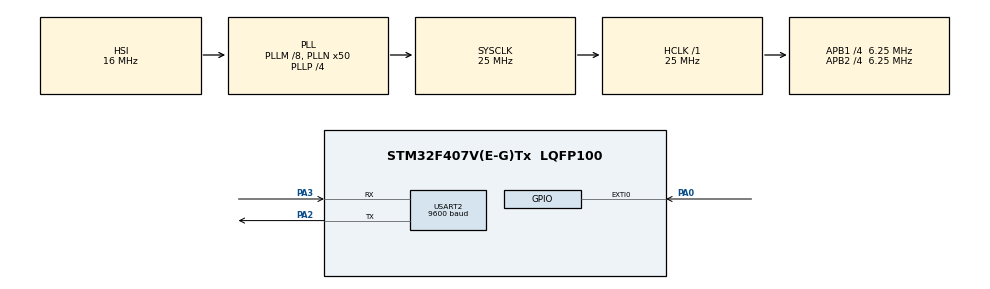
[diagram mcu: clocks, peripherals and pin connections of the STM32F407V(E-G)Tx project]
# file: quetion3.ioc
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Mcu.Family=STM32F4
RCC.CortexFreq_Value=25000000
RCC.APB1CLKDivider=RCC_HCLK_DIV4
NVIC.USART2_IRQn=true\:0\:0\:false\:false\:true\:true\:true
USART2.BaudRate=9600
RCC.SYSCLKSource=RCC_SYSCLKSOURCE_PLLCLK
ProjectManager.StackSize=0x400
PA0-WKUP.Signal=GPXTI0
PA3.Mode=Asynchronous
ProjectManager.TargetToolchain=STM32CubeIDE
RCC.HCLKFreq_Value=25000000
RCC.APB2TimFreq_Value=12500000
RCC.AHBFreq_Value=25000000
RCC.HSE_VALUE=8000000
board=STM32F407G-DISC1
RCC.VCOOutputFreq_Value=100000000
RCC.APB2Freq_Value=6250000
Mcu.Name=STM32F407V(E-G)Tx
PA2.Signal=USART2_TX
RCC.48MHZClocksFreq_Value=14285714.285714285
NVIC.EXTI0_IRQn=true\:0\:0\:false\:false\:true\:true\:true
RCC.SYSCLKFreq_VALUE=25000000
Mcu.Package=LQFP100
USART2.VirtualMode=VM_ASYNC
ProjectManager.HeapSize=0x200
RCC.HSI_VALUE=16000000
RCC.PLLP=RCC_PLLP_DIV4
RCC.PLLQ=7
NVIC.PriorityGroup=NVIC_PRIORITYGROUP_0
RCC.APB2CLKDivider=RCC_HCLK_DIV4
RCC.PLLM=8
RCC.PLLN=50
RCC.APB1TimFreq_Value=12500000
PA2.Mode=Asynchronous
RCC.APB1Freq_Value=6250000
PA3.Signal=USART2_RX

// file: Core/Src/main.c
/* USER CODE BEGIN Header */
/**
  ******************************************************************************
  * @file           : main.c
  * @brief          : Main program body
  ******************************************************************************
  * @attention
  *
  * <h2><center>&copy; Copyright (c) 2022 STMicroelectronics.
  * All rights reserved.</center></h2>
  *
  * This software component is licensed by ST under Ultimate Liberty license
  * SLA0044, the "License"; You may not use this file except in compliance with
  * the License. You may obtain a copy of the License at:
  *                             www.st.com/SLA0044
  *
  ******************************************************************************
  */
/* USER CODE END Header */
#include "main.h"

/* USER CODE BEGIN Includes */
#include<stdio.h>
#include<string.h>

/* USER CODE END Includes */

UART_HandleTypeDef huart2;

/* USER CODE BEGIN PV */
volatile int switch_flag = 0;

/* USER CODE END PV */

void SystemClock_Config(void);
static void MX_GPIO_Init(void);
static void MX_USART2_UART_Init(void);

int main(void)
{
  /* USER CODE BEGIN 1 */
	char str[64];
	int count = 0;

  /* USER CODE END 1 */

  /* MCU Configuration--------------------------------------------------------*/

  /* Reset of all peripherals, Initializes the Flash interface and the Systick. */
  HAL_Init();

  /* Configure the system clock */
  SystemClock_Config();

  /* Initialize all configured peripherals */
  MX_GPIO_Init();
  MX_USART2_UART_Init();

  /* Infinite loop */
  while (1)
  {
	  if(switch_flag == 1)
	  {
		  count++;

		  sprintf(str,"Count = %d\r\n",count);
		  HAL_UART_Transmit_IT(&huart2, (uint8_t*)str, strlen(str));
		  HAL_Delay(1000);
		  switch_flag =0;
	  }

  }
}

void SystemClock_Config(void)
{
  RCC_OscInitTypeDef RCC_OscInitStruct = {0};
  RCC_ClkInitTypeDef RCC_ClkInitStruct = {0};

  /** Configure the main internal regulator output voltage
  */
  __HAL_RCC_PWR_CLK_ENABLE();
  __HAL_PWR_VOLTAGESCALING_CONFIG(PWR_REGULATOR_VOLTAGE_SCALE1);
  /** Initializes the RCC Oscillators according to the specified parameters
  * in the RCC_OscInitTypeDef structure.
  */
  RCC_OscInitStruct.OscillatorType = RCC_OSCILLATORTYPE_HSI;
  RCC_OscInitStruct.HSIState = RCC_HSI_ON;
  RCC_OscInitStruct.HSICalibrationValue = RCC_HSICALIBRATION_DEFAULT;
  RCC_OscInitStruct.PLL.PLLState = RCC_PLL_ON;
  RCC_OscInitStruct.PLL.PLLSource = RCC_PLLSOURCE_HSI;
  RCC_OscInitStruct.PLL.PLLM = 8;
  RCC_OscInitStruct.PLL.PLLN = 50;
  RCC_OscInitStruct.PLL.PLLP = RCC_PLLP_DIV4;
  RCC_OscInitStruct.PLL.PLLQ = 7;
  if (HAL_RCC_OscConfig(&RCC_OscInitStruct) != HAL_OK)
  {
    Error_Handler();
  }
  /** Initializes the CPU, AHB and APB buses clocks
  */
  RCC_ClkInitStruct.ClockType = RCC_CLOCKTYPE_HCLK|RCC_CLOCKTYPE_SYSCLK
                              |RCC_CLOCKTYPE_PCLK1|RCC_CLOCKTYPE_PCLK2;
  RCC_ClkInitStruct.SYSCLKSource = RCC_SYSCLKSOURCE_PLLCLK;
  RCC_ClkInitStruct.AHBCLKDivider = RCC_SYSCLK_DIV1;
  RCC_ClkInitStruct.APB1CLKDivider = RCC_HCLK_DIV4;
  RCC_ClkInitStruct.APB2CLKDivider = RCC_HCLK_DIV4;

  if (HAL_RCC_ClockConfig(&RCC_ClkInitStruct, FLASH_LATENCY_0) != HAL_OK)
  {
    Error_Handler();
  }
}

static void MX_USART2_UART_Init(void)
{

  huart2.Instance = USART2;
  huart2.Init.BaudRate = 9600;
  huart2.Init.WordLength = UART_WORDLENGTH_8B;
  huart2.Init.StopBits = UART_STOPBITS_1;
  huart2.Init.Parity = UART_PARITY_NONE;
  huart2.Init.Mode = UART_MODE_TX_RX;
  huart2.Init.HwFlowCtl = UART_HWCONTROL_NONE;
  huart2.Init.OverSampling = UART_OVERSAMPLING_16;
  if (HAL_UART_Init(&huart2) != HAL_OK)
  {
    Error_Handler();
  }

}

static void MX_GPIO_Init(void)
{
  GPIO_InitTypeDef GPIO_InitStruct = {0};

  /* GPIO Ports Clock Enable */
  __HAL_RCC_GPIOA_CLK_ENABLE();

  /*Configure GPIO pin : PA0 */
  GPIO_InitStruct.Pin = GPIO_PIN_0;
  GPIO_InitStruct.Mode = GPIO_MODE_IT_RISING;
  GPIO_InitStruct.Pull = GPIO_NOPULL;
  HAL_GPIO_Init(GPIOA, &GPIO_InitStruct);

  /* EXTI interrupt init*/
  HAL_NVIC_SetPriority(EXTI0_IRQn, 0, 0);
  HAL_NVIC_EnableIRQ(EXTI0_IRQn);

}

/* USER CODE BEGIN 4 */

void HAL_GPIO_EXTI_Callback(uint16_t GPIO_PIN)
{
	switch_flag =1;
}

/* USER CODE END 4 */

void Error_Handler(void)
{
  __disable_irq();
  while (1)
  {
  }
}

/************************ (C) COPYRIGHT STMicroelectronics *****END OF FILE****/
